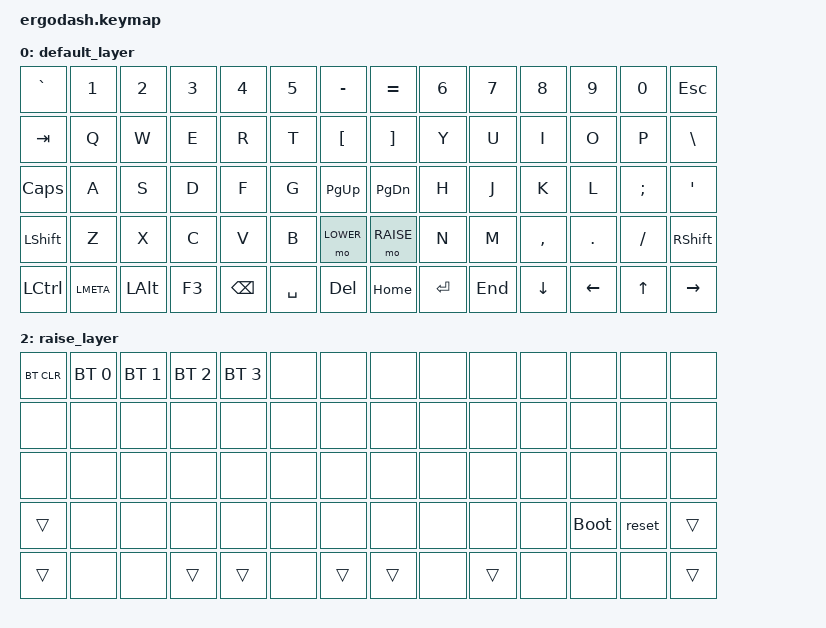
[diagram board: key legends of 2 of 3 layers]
/*
 * Copyright (c) 2020 The ZMK Contributors
 *
 * SPDX-License-Identifier: MIT
 */

#include <behaviors.dtsi>
#include <dt-bindings/zmk/keys.h>
#include <dt-bindings/zmk/rgb.h>
#include <dt-bindings/zmk/bt.h>

#define DEFAULT 0
#define LOWER   1
#define RAISE   2


/ {
        keymap {
                compatible = "zmk,keymap";

                default_layer {
/* QWERTY
 * .----------------------------------------------------------------------------------------------------------------------.
 * |  `   |   1  |   2  |   3  |   4  |   5  |  -   |                    |  =   |   6  |   7  |   8  |   9  |   0  | ESC  |
 * |------+------+------+------+------+------+------+--------------------+------+------+------+------+------+------+------|
 * | Tab  |   Q  |   W  |   E  |   R  |   T  |  [   |                    |  ]   |   Y  |   U  |   I  |   O  |   P  |  \   |
 * |------+------+------+------+------+------+------+--------------------+------+------+------+------+------+------+------|
 * | Caps |   A  |   S  |   D  |   F  |   G  | PGUP |                    | PGDN |   H  |   J  |   K  |   L  |   ;  |  '   |
 * |------+------+------+------+------+------+---------------------------+------+------+------+------+------+------+------|
 * | Shift|   Z  |   X  |   C  |   V  |   B  | Lower|                    | Raise|   N  |   M  |   ,  |   .  |   /  | Shift|
 * |-------------+------+------+------+------+------+------+------+------+------+------+------+------+------+-------------|
 * | Ctrl | Win  | Alt  |  F3  | BSPC | Space| Del  |                    | Home | Enter|  End | Down | Left |  Up  | Right|
 * .----------------------------------------------------------------------------------------------------------------------.
 */
                        bindings = <
&kp  GRAVE    &kp  N1       &kp  N2       &kp  N3       &kp  N4       &kp  N5       &kp  MINUS             &kp  EQUAL    &kp  N6       &kp  N7       &kp  N8       &kp  N9       &kp  N0       &kp  ESC
&kp  TAB      &kp  Q        &kp  W        &kp  E        &kp  R        &kp  T        &kp  LBKT              &kp  RBKT     &kp  Y        &kp  U        &kp  I        &kp  O        &kp  P        &kp  BSLH
&kp  CAPSLOCK &kp  A        &kp  S        &kp  D        &kp  F        &kp  G        &kp  PG_UP             &kp  PG_DN    &kp  H        &kp  J        &kp  K        &kp  L        &kp  SEMI     &kp  SQT
&kp  LSHFT    &kp  Z        &kp  X        &kp  C        &kp  V        &kp  B        &mo  LOWER             &mo  RAISE    &kp  N        &kp  M        &kp  COMMA    &kp  DOT      &kp  SLASH    &kp  RSHFT
&kp  LCTRL    &kp  LMETA    &kp  LALT     &kp  F3       &kp  BSPC     &kp  SPACE    &kp  DEL               &kp  HOME     &kp  RET      &kp  END      &kp  DOWN     &kp  LEFT     &kp  UP       &kp  RIGHT
                        >;
                };
                lower_layer {
/* .----------------------------------------------------------------------------------------------------------------------.
 * |  F11 |  F1  |  F2  |  F3  |  F4  |  F5  |      |                    |      |  F6  |  F7  |  F8  |  F9  |  F10 |  F12 |
 * |------+------+------+------+------+------+------+--------------------+------+------+------+------+------+------+------|
 * |  TOG |      |      |      |      |      |      |                    |      |      |      |      |      |      |      |
 * |------+------+------+------+------+------+------+--------------------+------+------+------+------+------+------+------|
 * | HUEI | HUED | BRI  | BRD  |      |      |      |                    |      |      |      |      |      |      |      |
 * |------+------+------+------+------+------+---------------------------+------+------+------+------+------+------+------|
 * | Shift| Boot | Reset|      |      |      |      |                    |      |      |      |      |      |      | Shift|
 * |-------------+------+------+------+------+------+------+------+------+------+------+------+------+------+-------------|
 * | Ctlr |      |      |  Win |||||||| Alt  |      | Lower|||||||| Raise|      | RAlt ||||||||      |      |      | RCtrl|
 * .----------------------------------------------------------------------------------------------------------------------.
 */ /* FIXME boot and reset are not yet locale aware */
                        bindings = <
&kp  F11        &kp  F1         &kp  F2         &kp  F3       &kp  F4       &kp  F5       &kp  &none             &kp  &none    &kp  F6       &kp  F7       &kp  F8       &kp  F9       &kp  F10      &kp  F12
&rgb_ug RGB_TOG &none           &none           &none         &none         &none         &none                  &none         &none         &none         &none         &none         &none         &none
&rgb_ug RGB_HUI &rgb_ug RGB_HUD &rgb_ug RGB_BRI &rgb_ug RGB_BRD         &none         &none         &none                  &none         &none         &none         &none         &none         &none         &none
&trans          &bootloader     &reset          &none         &none         &none         &none                  &none         &none         &none         &none         &none         &none         &trans
&trans          &none           &none           &trans        &trans        &none         &trans                 &trans        &none         &trans        &none         &none         &none         &trans
                        >;
                };
                raise_layer {
/* .----------------------------------------------------------------------------------------------------------------------.
 * | BTCL | BT 0 | BT 1 | BT 2 | BT 3 |      |      |                    |      |      |      |      |      |      |      |
 * |------+------+------+------+------+------+------+--------------------+------+------+------+------+------+------+------|
 * |      |      |      |      |      |      |      |                    |      |      |      |      |      |      |      |
 * |------+------+------+------+------+------+------+--------------------+------+------+------+------+------+------+------|
 * |      |      |      |      |      |      |      |                    |      |      |      |      |      |      |      |
 * |------+------+------+------+------+------+---------------------------+------+------+------+------+------+------+------|
 * | Shift|      |      |      |      |      |      |                    |      |      |      |      | Boot | Reset| Shift|
 * |-------------+------+------+------+------+------+------+------+------+------+------+------+------+------+-------------|
 * | Ctlr |      |      |  Win |||||||| Alt  |      | Lower|||||||| Raise|      | RAlt ||||||||      |      |      | RCtrl|
 * .----------------------------------------------------------------------------------------------------------------------.
 */ /* FIXME boot and reset are not yet locale aware */
                        bindings = <
&bt BT_CLR    &bt BT_SEL 0  &bt BT_SEL 1  &bt BT_SEL 2  &bt BT_SEL 3  &none         &none             &none         &none         &none         &none         &none         &none         &none
&none         &none         &none         &none         &none         &none         &none                  &none         &none         &none         &none         &none         &none         &none
&none         &none         &none         &none         &none         &none         &none                  &none         &none         &none         &none         &none         &none         &none
&trans        &none         &none         &none         &none         &none         &none                  &none         &none         &none         &none         &bootloader   &reset        &trans
&trans        &none         &none         &trans        &trans        &none         &trans                 &trans        &none         &trans        &none         &none         &none         &trans
                        >;
                };
        };
};

